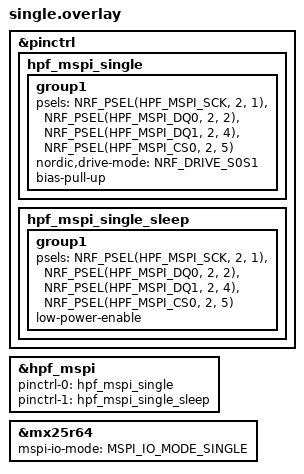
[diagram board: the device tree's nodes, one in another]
&pinctrl {
	hpf_mspi_single: hpf_mspi_single {
		group1 {
			psels = <NRF_PSEL(HPF_MSPI_SCK, 2, 1)>,
				<NRF_PSEL(HPF_MSPI_DQ0, 2, 2)>,
				<NRF_PSEL(HPF_MSPI_DQ1, 2, 4)>,
				<NRF_PSEL(HPF_MSPI_CS0, 2, 5)>;
			nordic,drive-mode = <NRF_DRIVE_S0S1>;
			bias-pull-up;
		};
	};

	hpf_mspi_single_sleep: hpf_mspi_single_sleep {
		group1 {
			psels = <NRF_PSEL(HPF_MSPI_SCK, 2, 1)>,
				<NRF_PSEL(HPF_MSPI_DQ0, 2, 2)>,
				<NRF_PSEL(HPF_MSPI_DQ1, 2, 4)>,
				<NRF_PSEL(HPF_MSPI_CS0, 2, 5)>;
			low-power-enable;
		};
	};
};

&hpf_mspi {
	pinctrl-0 = <&hpf_mspi_single>;
	pinctrl-1 = <&hpf_mspi_single_sleep>;
};

&mx25r64 {
	mspi-io-mode = "MSPI_IO_MODE_SINGLE";
};
